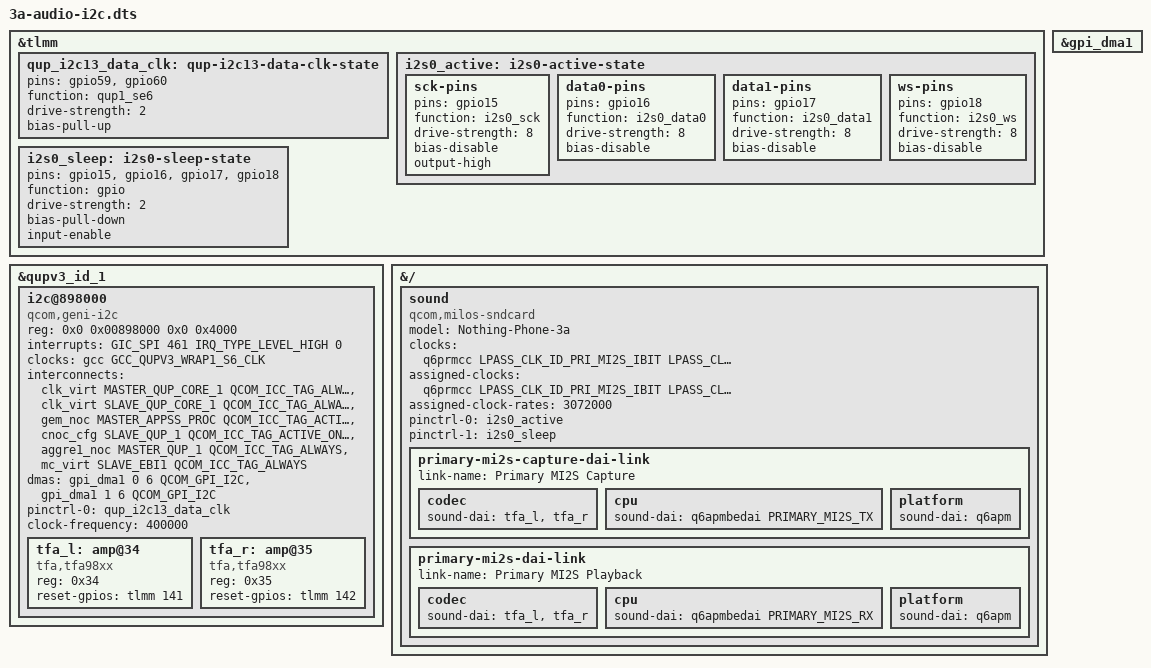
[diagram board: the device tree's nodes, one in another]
// SPDX-License-Identifier: BSD-3-Clause
/*
 * Nothing Phone (3a) speaker amps, stage A of AUDIO-PLAN.md: only the I2C bus (QUP1 SE6,
 * i2c@898000, as Nura's i2c13 on the Phone (4a)), no amp driver, so the TFA98xx can only be
 * read. Their resets (gpio141/142, active high on TFA) are left alone here.
 * Applied at runtime by 3a-ovl-audio-i2c.ko.
 */
/dts-v1/;
/plugin/;

#include <dt-bindings/clock/qcom,milos-gcc.h>
#include <dt-bindings/dma/qcom-gpi.h>
#include <dt-bindings/gpio/gpio.h>
#include <dt-bindings/sound/qcom,q6afe.h>
#include <dt-bindings/sound/qcom,q6dsp-lpass-ports.h>
#include <dt-bindings/interconnect/qcom,icc.h>
#include <dt-bindings/interconnect/qcom,milos-rpmh.h>
#include <dt-bindings/interrupt-controller/arm-gic.h>

&tlmm {
	qup_i2c13_data_clk: qup-i2c13-data-clk-state {
		/* SDA, SCL */
		pins = "gpio59", "gpio60";
		function = "qup1_se6";
		drive-strength = <2>;
		bias-pull-up;
	};
};

&gpi_dma1 {
	status = "okay";
};

&qupv3_id_1 {
	#address-cells = <2>;
	#size-cells = <2>;
	status = "okay";

	i2c@898000 {
		compatible = "qcom,geni-i2c";
		reg = <0x0 0x00898000 0x0 0x4000>;

		interrupts = <GIC_SPI 461 IRQ_TYPE_LEVEL_HIGH 0>;

		clocks = <&gcc GCC_QUPV3_WRAP1_S6_CLK>;
		clock-names = "se";

		interconnects = <&clk_virt MASTER_QUP_CORE_1 QCOM_ICC_TAG_ALWAYS
				 &clk_virt SLAVE_QUP_CORE_1 QCOM_ICC_TAG_ALWAYS>,
				<&gem_noc MASTER_APPSS_PROC QCOM_ICC_TAG_ACTIVE_ONLY
				 &cnoc_cfg SLAVE_QUP_1 QCOM_ICC_TAG_ACTIVE_ONLY>,
				<&aggre1_noc MASTER_QUP_1 QCOM_ICC_TAG_ALWAYS
				 &mc_virt SLAVE_EBI1 QCOM_ICC_TAG_ALWAYS>;
		interconnect-names = "qup-core",
				     "qup-config",
				     "qup-memory";

		dmas = <&gpi_dma1 0 6 QCOM_GPI_I2C>,
		       <&gpi_dma1 1 6 QCOM_GPI_I2C>;
		dma-names = "tx",
			    "rx";

		pinctrl-0 = <&qup_i2c13_data_clk>;
		pinctrl-names = "default";

		clock-frequency = <400000>;

		#address-cells = <1>;
		#size-cells = <0>;

		status = "okay";

		/*
		 * Stage B: the two TFA9873 as in the vendor DT (no irq line, reset pulse active
		 * high). The ported snd-soc-tfa98xx.ko is not in the module tree, so nothing binds
		 * them until it is insmod'ed by hand; with allow_start=0 it never powers them up.
		 */
		tfa_l: amp@34 {
			compatible = "tfa,tfa98xx";
			reg = <0x34>;
			reset-gpios = <&tlmm 141 GPIO_ACTIVE_HIGH>;
			#sound-dai-cells = <0>;
		};

		tfa_r: amp@35 {
			compatible = "tfa,tfa98xx";
			reg = <0x35>;
			reset-gpios = <&tlmm 142 GPIO_ACTIVE_HIGH>;
			#sound-dai-cells = <0>;
		};
	};
};

/*
 * Sound card as Nura's on the Phone (4a): Primary MI2S to both amps (SD1 playback, SD0 IV
 * feedback), AudioReach topology qcom/milos/Nothing-Phone-3a-tplg.bin. Speaker protection is not
 * in the graph yet: the amps stay powered down (snd-soc-tfa98xx allow_start=0).
 */
&tlmm {
	i2s0_active: i2s0-active-state {
		sck-pins {
			pins = "gpio15";
			function = "i2s0_sck";
			drive-strength = <8>;
			bias-disable;
			output-high;
		};
		data0-pins {
			pins = "gpio16";
			function = "i2s0_data0";
			drive-strength = <8>;
			bias-disable;
		};
		data1-pins {
			pins = "gpio17";
			function = "i2s0_data1";
			drive-strength = <8>;
			bias-disable;
		};
		ws-pins {
			pins = "gpio18";
			function = "i2s0_ws";
			drive-strength = <8>;
			bias-disable;
		};
	};

	i2s0_sleep: i2s0-sleep-state {
		pins = "gpio15", "gpio16", "gpio17", "gpio18";
		function = "gpio";
		drive-strength = <2>;
		bias-pull-down;
		input-enable;
	};
};

&{/} {
	sound {
		compatible = "qcom,milos-sndcard";
		model = "Nothing-Phone-3a";

		/* primary MI2S bit clock, 48 kHz x 2 x 32 bit, as Android's AGM requests it */
		clocks = <&q6prmcc LPASS_CLK_ID_PRI_MI2S_IBIT LPASS_CLK_ATTRIBUTE_COUPLE_NO>;
		clock-names = "pri-mi2s-ibit";
		assigned-clocks = <&q6prmcc LPASS_CLK_ID_PRI_MI2S_IBIT LPASS_CLK_ATTRIBUTE_COUPLE_NO>;
		assigned-clock-rates = <3072000>;

		pinctrl-0 = <&i2s0_active>;
		pinctrl-1 = <&i2s0_sleep>;
		pinctrl-names = "default", "sleep";

		primary-mi2s-capture-dai-link {
			link-name = "Primary MI2S Capture";

			codec {
				sound-dai = <&tfa_l>, <&tfa_r>;
			};

			cpu {
				sound-dai = <&q6apmbedai PRIMARY_MI2S_TX>;
			};

			platform {
				sound-dai = <&q6apm>;
			};
		};

		primary-mi2s-dai-link {
			link-name = "Primary MI2S Playback";

			codec {
				sound-dai = <&tfa_l>, <&tfa_r>;
			};

			cpu {
				sound-dai = <&q6apmbedai PRIMARY_MI2S_RX>;
			};

			platform {
				sound-dai = <&q6apm>;
			};
		};
	};
};
